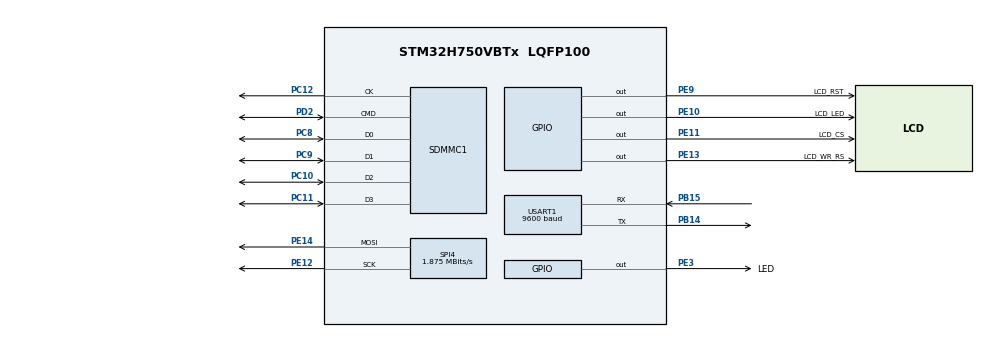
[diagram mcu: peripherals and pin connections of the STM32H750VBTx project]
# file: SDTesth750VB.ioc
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FATFS._CODE_PAGE=437
FATFS._FS_EXFAT=1
FATFS._MAX_SS=4096
FATFS._USE_LFN=2
FREERTOS.Tasks01=LEDTASK,24,128,LedTask,Default,NULL,Dynamic,NULL,NULL;SD_TASK,8,1024,sdCardUpdata,Default,NULL,Dynamic,NULL,NULL
Mcu.Family=STM32H7
Mcu.Name=STM32H750VBTx
Mcu.Package=LQFP100
NVIC.PriorityGroup=NVIC_PRIORITYGROUP_4
NVIC.SDMMC1_IRQn=true\:7\:0\:true\:false\:true\:true\:true\:true\:true
NVIC.TIM16_IRQn=true\:15\:0\:false\:false\:true\:false\:false\:true\:true
NVIC.TimeBase=TIM16_IRQn
NVIC.TimeBaseIP=TIM16
PA13\ (JTMS/SWDIO).Mode=Serial_Wire
PA13\ (JTMS/SWDIO).Signal=DEBUG_JTMS-SWDIO
PA14\ (JTCK/SWCLK).Mode=Serial_Wire
PA14\ (JTCK/SWCLK).Signal=DEBUG_JTCK-SWCLK
PB14.Mode=Asynchronous
PB14.Signal=USART1_TX
PB15.Mode=Asynchronous
PB15.Signal=USART1_RX
PC10.GPIO_PuPd=GPIO_PULLUP
PC10.Mode=SD_4_bits_Wide_bus
PC10.Signal=SDMMC1_D2
PC11.GPIO_PuPd=GPIO_PULLUP
PC11.Mode=SD_4_bits_Wide_bus
PC11.Signal=SDMMC1_D3
PC12.Mode=SD_4_bits_Wide_bus
PC12.Signal=SDMMC1_CK
PC8.GPIO_PuPd=GPIO_PULLUP
PC8.Mode=SD_4_bits_Wide_bus
PC8.Signal=SDMMC1_D0
PC9.GPIO_PuPd=GPIO_PULLUP
PC9.Mode=SD_4_bits_Wide_bus
PC9.Signal=SDMMC1_D1
PD2.GPIO_PuPd=GPIO_PULLUP
PD2.Mode=SD_4_bits_Wide_bus
PD2.Signal=SDMMC1_CMD
PE10.GPIO_Label=LCD_LED
PE10.Signal=GPIO_Output
PE11.GPIO_Label=LCD_CS
PE11.Signal=GPIO_Output
PE12.Mode=TX_Only_Simplex_Unidirect_Master
PE12.Signal=SPI4_SCK
PE13.GPIO_Label=LCD_WR_RS
PE13.Signal=GPIO_Output
PE14.Mode=TX_Only_Simplex_Unidirect_Master
PE14.Signal=SPI4_MOSI
PE3.GPIO_Label=LED
PE3.Signal=GPIO_Output
PE9.GPIO_Label=LCD_RST
PE9.Signal=GPIO_Output
PH0-OSC_IN\ (PH0).Mode=HSE-External-Oscillator
PH0-OSC_IN\ (PH0).Signal=RCC_OSC_IN
PH1-OSC_OUT\ (PH1).Mode=HSE-External-Oscillator
PH1-OSC_OUT\ (PH1).Signal=RCC_OSC_OUT
ProjectManager.HeapSize=0x1000
ProjectManager.StackSize=0x1000
ProjectManager.TargetToolchain=MDK-ARM V5.32
RCC.ADCFreq_Value=50390625
RCC.APB1Freq_Value=120000000
RCC.APB2Freq_Value=120000000
RCC.APB3Freq_Value=120000000
RCC.APB4Freq_Value=120000000
RCC.CortexFreq_Value=480000000
RCC.D1PPRE=RCC_APB3_DIV2
RCC.D2PPRE1=RCC_APB1_DIV2
RCC.D2PPRE2=RCC_APB2_DIV2
RCC.D3PPRE=RCC_APB4_DIV2
RCC.DIVM1=5
RCC.DIVN1=192
RCC.DIVQ1=20
RCC.HCLKFreq_Value=240000000
RCC.HPRE=RCC_HCLK_DIV2
RCC.PLL2FRACN=0
RCC.PLL3FRACN=0
RCC.PLLFRACN=0
RCC.PLLSourceVirtual=RCC_PLLSOURCE_HSE
RCC.SYSCLKFreq_VALUE=480000000
RCC.SYSCLKSource=RCC_SYSCLKSOURCE_PLLCLK
RCC.USBFreq_Value=48000000
SDMMC1.ClockDiv=5
SPI4.BaudRatePrescaler=SPI_BAUDRATEPRESCALER_64
SPI4.CalculateBaudRate=1.875 MBits/s
SPI4.DataSize=SPI_DATASIZE_8BIT
SPI4.Direction=SPI_DIRECTION_2LINES_TXONLY
SPI4.Mode=SPI_MODE_MASTER
SPI4.VirtualType=VM_MASTER
TIM5.Channel-PWM\ Generation1\ No\ Output=TIM_CHANNEL_1
USART1.BaudRate=9600
USART1.VirtualMode-Asynchronous=VM_ASYNC
VP_FATFS_VS_SDIO.Mode=SDIO
VP_FREERTOS_VS_CMSIS_V2.Mode=CMSIS_V2
VP_SYS_VS_tim16.Mode=TIM16
VP_TIM5_VS_no_output1.Mode=PWM Generation1 No Output
board=custom

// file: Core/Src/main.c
/* USER CODE BEGIN Header */
/**
  ******************************************************************************
  * @file           : main.c
  * @brief          : Main program body
  ******************************************************************************
  * @attention
  *
  * Copyright (c) 2023 STMicroelectronics.
  * All rights reserved.
  *
  * This software is licensed under terms that can be found in the LICENSE file
  * in the root directory of this software component.
  * If no LICENSE file comes with this software, it is provided AS-IS.
  *
  ******************************************************************************
  */
/* USER CODE END Header */
#include "main.h"
#include "cmsis_os.h"
#include "fatfs.h"
#include "sdmmc.h"
#include "spi.h"
#include "tim.h"
#include "usart.h"
#include "gpio.h"

/* USER CODE BEGIN Includes */
#include "lcd.h"
/* USER CODE END Includes */

void SystemClock_Config(void);
void MX_FREERTOS_Init(void);

int main(void)
{

  /* MCU Configuration--------------------------------------------------------*/

  /* Reset of all peripherals, Initializes the Flash interface and the Systick. */
  HAL_Init();

  /* Configure the system clock */
  SystemClock_Config();

  /* Initialize all configured peripherals */
  MX_GPIO_Init();
  MX_SDMMC1_SD_Init();
  MX_USART1_UART_Init();
  MX_FATFS_Init();
  MX_SPI4_Init();
  MX_TIM5_Init();
  /* USER CODE BEGIN 2 */
  /*What we use, what increases the price*/
  HAL_GPIO_WritePin(LCD_LED_GPIO_Port, LCD_LED_Pin, GPIO_PIN_RESET);

	LCD_Init(BLACK);
//	uint8_t text[20];
//	sprintf((char *)&text, "What we use, what");
//	LCD_ShowString(4, 20, ST7735Ctx.Width, 16, 16, text);
//
//	sprintf((char *)&text, "increases the price");
//	LCD_ShowString(4, 40, ST7735Ctx.Width, 16, 16, text);

	LCD_STRing(4, 20, "ThatGood!", DARKBLUE, DARKBLUE, GREEN);

//		status = f_mount(&SDFatFS, (const TCHAR*)SDPath, 0);
//	if(status == FR_OK)
		printf("mount_success\r\n");
  /* USER CODE END 2 */

  /* Init scheduler */
  osKernelInitialize();  /* Call init function for freertos objects (in freertos.c) */
  MX_FREERTOS_Init();

  /* Start scheduler */
  osKernelStart();

  /* We should never get here as control is now taken by the scheduler */
  /* Infinite loop */
  while (1)
  {

  }
}

void SystemClock_Config(void)
{
  RCC_OscInitTypeDef RCC_OscInitStruct = {0};
  RCC_ClkInitTypeDef RCC_ClkInitStruct = {0};

  /** Supply configuration update enable
  */
  HAL_PWREx_ConfigSupply(PWR_LDO_SUPPLY);

  /** Configure the main internal regulator output voltage
  */
  __HAL_PWR_VOLTAGESCALING_CONFIG(PWR_REGULATOR_VOLTAGE_SCALE1);

  while(!__HAL_PWR_GET_FLAG(PWR_FLAG_VOSRDY)) {}

  __HAL_RCC_SYSCFG_CLK_ENABLE();
  __HAL_PWR_VOLTAGESCALING_CONFIG(PWR_REGULATOR_VOLTAGE_SCALE0);

  while(!__HAL_PWR_GET_FLAG(PWR_FLAG_VOSRDY)) {}

  /** Initializes the RCC Oscillators according to the specified parameters
  * in the RCC_OscInitTypeDef structure.
  */
  RCC_OscInitStruct.OscillatorType = RCC_OSCILLATORTYPE_HSE;
  RCC_OscInitStruct.HSEState = RCC_HSE_ON;
  RCC_OscInitStruct.PLL.PLLState = RCC_PLL_ON;
  RCC_OscInitStruct.PLL.PLLSource = RCC_PLLSOURCE_HSE;
  RCC_OscInitStruct.PLL.PLLM = 5;
  RCC_OscInitStruct.PLL.PLLN = 192;
  RCC_OscInitStruct.PLL.PLLP = 2;
  RCC_OscInitStruct.PLL.PLLQ = 20;
  RCC_OscInitStruct.PLL.PLLR = 2;
  RCC_OscInitStruct.PLL.PLLRGE = RCC_PLL1VCIRANGE_2;
  RCC_OscInitStruct.PLL.PLLVCOSEL = RCC_PLL1VCOWIDE;
  RCC_OscInitStruct.PLL.PLLFRACN = 0;
  if (HAL_RCC_OscConfig(&RCC_OscInitStruct) != HAL_OK)
  {
    Error_Handler();
  }

  /** Initializes the CPU, AHB and APB buses clocks
  */
  RCC_ClkInitStruct.ClockType = RCC_CLOCKTYPE_HCLK|RCC_CLOCKTYPE_SYSCLK
                              |RCC_CLOCKTYPE_PCLK1|RCC_CLOCKTYPE_PCLK2
                              |RCC_CLOCKTYPE_D3PCLK1|RCC_CLOCKTYPE_D1PCLK1;
  RCC_ClkInitStruct.SYSCLKSource = RCC_SYSCLKSOURCE_PLLCLK;
  RCC_ClkInitStruct.SYSCLKDivider = RCC_SYSCLK_DIV1;
  RCC_ClkInitStruct.AHBCLKDivider = RCC_HCLK_DIV2;
  RCC_ClkInitStruct.APB3CLKDivider = RCC_APB3_DIV2;
  RCC_ClkInitStruct.APB1CLKDivider = RCC_APB1_DIV2;
  RCC_ClkInitStruct.APB2CLKDivider = RCC_APB2_DIV2;
  RCC_ClkInitStruct.APB4CLKDivider = RCC_APB4_DIV2;

  if (HAL_RCC_ClockConfig(&RCC_ClkInitStruct, FLASH_LATENCY_4) != HAL_OK)
  {
    Error_Handler();
  }
}

void HAL_TIM_PeriodElapsedCallback(TIM_HandleTypeDef *htim)
{
  if (htim->Instance == TIM16) {
    HAL_IncTick();
  }
}

void Error_Handler(void)
{
  __disable_irq();
  while (1)
  {
  }
}

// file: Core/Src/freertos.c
/* USER CODE BEGIN Header */
/**
  ******************************************************************************
  * File Name          : freertos.c
  * Description        : Code for freertos applications
  ******************************************************************************
  * @attention
  *
  * Copyright (c) 2023 STMicroelectronics.
  * All rights reserved.
  *
  * This software is licensed under terms that can be found in the LICENSE file
  * in the root directory of this software component.
  * If no LICENSE file comes with this software, it is provided AS-IS.
  *
  ******************************************************************************
  */
/* USER CODE END Header */

#include "FreeRTOS.h"
#include "task.h"
#include "main.h"
#include "cmsis_os.h"

/* USER CODE BEGIN Includes */
#include "usart.h"
#include "stdio.h"
#include "fatfs.h"
#include "lcd.h"
/* USER CODE END Includes */

/* Definitions for LEDTASK */
osThreadId_t LEDTASKHandle;
const osThreadAttr_t LEDTASK_attributes = {
  .name = "LEDTASK",
  .stack_size = 128 * 4,
  .priority = (osPriority_t) osPriorityNormal,
};
/* Definitions for SD_TASK */
osThreadId_t SD_TASKHandle;
const osThreadAttr_t SD_TASK_attributes = {
  .name = "SD_TASK",
  .stack_size = 1024 * 4,
  .priority = (osPriority_t) osPriorityLow,
};

void LedTask(void *argument);
void sdCardUpdata(void *argument);

void MX_FREERTOS_Init(void); /* (MISRA C 2004 rule 8.1) */

void MX_FREERTOS_Init(void) {

  /* Create the thread(s) */
  /* creation of LEDTASK */
  LEDTASKHandle = osThreadNew(LedTask, NULL, &LEDTASK_attributes);

  /* creation of SD_TASK */
  SD_TASKHandle = osThreadNew(sdCardUpdata, NULL, &SD_TASK_attributes);

}

void LedTask(void *argument)
{
  /* USER CODE BEGIN LedTask */
	uint8_t status = 0;
  /* Infinite loop */
  for(;;)
  {

	  HAL_GPIO_TogglePin(LED_GPIO_Port, LED_Pin);
	  printf("Running\r\n");
//	  if(status == 0){
//		uint8_t text[20];
//		sprintf((char *)&text, "What we use, what");
//		LCD_ShowString(4, 20, ST7735Ctx.Width, 16, 16, text);
//
//		sprintf((char *)&text, "increases the price");
//		LCD_ShowString(4, 40, ST7735Ctx.Width, 16, 16, text);
//
//	  }
//	  else
//		  ST7735_LCD_Driver.FillRect(&st7735_pObj, 0, 0, ST7735Ctx.Width,ST7735Ctx.Height, BLACK);
//	  status = !status;
    osDelay(500);
  }
  /* USER CODE END LedTask */
}

void sdCardUpdata(void *argument)
{
  /* USER CODE BEGIN sdCardUpdata */
  /* Infinite loop */
  for(;;)
  {
//	  test();
    osDelay(1000);
  }
  /* USER CODE END sdCardUpdata */
}
